# STM32N655 register map
File version: 1.0
CPU: CM55 r0p1, little endian, no MPU, FPU, vendor SysTick, 8 interrupt priority bits
Registers are 32-bit, read-write, reset 0x0 unless marked. A register's access mark holds for its fields unless they carry their own. Offsets are from the block's base; [hi:lo] are bit positions; {n}, {i} and the like mark numbered series; 'fields as' and 'values as' point back to an identical list.

## FMC1 — Flexible memory controller
Base 0x48024000
Same registers: FMC1_S 0x58024000
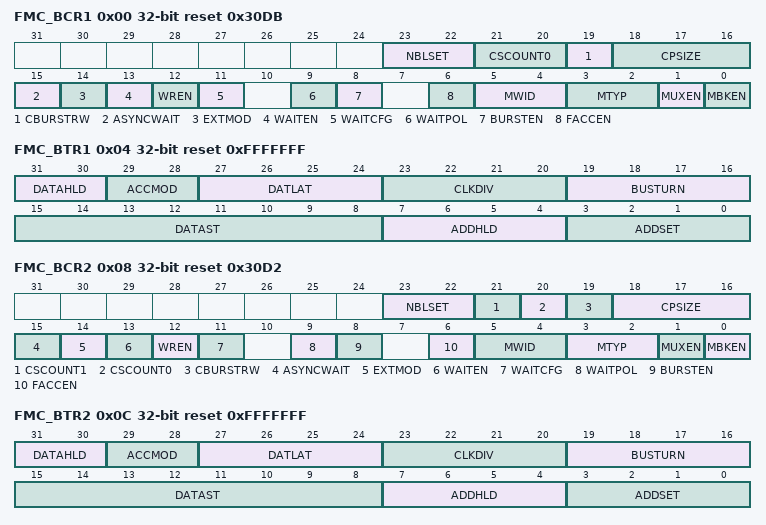
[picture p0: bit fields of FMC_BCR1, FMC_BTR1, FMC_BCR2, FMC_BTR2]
0x00 FMC_BCR1 reset 0x30DB — SRAM/NOR Flash chip-select control register for memory region 1
  [23:22] NBLSET — Byte lane (NBL) setup
    0=NBL setup time is 0 fmc_ker_ck clock cycle; 1=NBL setup time is 1 fmc_ker_ck clock cycle; 2=NBL setup time is 2 fmc_ker_ck clock cycles; 3=NBL setup time is 3 fmc_ker_ck clock cycles
  [21:20] CSCOUNT0 — Chip Select (CS) counter
    0=Counter disabled; 1=NEx deasserted after fmc_ker_ck clock cycle; 2=NEx deasserted after 64 fmc_ker_ck clock cycles; 3=NEx deasserted after 256 fmc_ker_ck clock cycles
  [19] CBURSTRW — Write burst enable
    0=Write operations are always performed in asynchronous mode; 1=Write operations are performed in synchronous mode
  [18:16] CPSIZE — CRAM page size
    0=No burst split when crossing page boundary. (default after reset).; 1=128 bytes; 2=256 bytes; 3=512 bytes; 4=1024 bytes
  [15] ASYNCWAIT — Wait signal during asynchronous transfers
    0=NWAIT signal not taken in to account during asynchronous transfers (default after reset); 1=NWAIT signal taken in to account during asynchronous transfers
  [14] EXTMOD — Extended mode enable
    0=Values inside FMC_BWTR register not taken into account (default after reset); 1=Values inside FMC_BWTR register taken into account
  [13] WAITEN — Wait enable bit
    0=NWAIT signal disabled (its level not taken into account, no wait state inserted after the programmed Flash latency period); 1=NWAIT signal enabled (its level is taken into account after the programmed latency period to insert wait states if asserted) (default after reset)
  [12] WREN — Write enable bit
    0=Write operations to the memory region by the FMC disabled. An AXI slave error is reported,; 1=Write operations to the memory region by the FMC enabled (default after reset)
  [11] WAITCFG — Wait timing configuration
    0=NWAIT signal active one data cycle before wait state (default after reset),; 1=NWAIT signal active during wait state (not used for PSRAM)
  [9] WAITPOL — Wait signal polarity bit
    0=NWAIT active low (default after reset),; 1=NWAIT active high
  [8] BURSTEN — Burst enable bit
    0=Burst mode disabled (default after reset). Read accesses are performed in asynchronous mode.; 1=Burst mode enable. Read accesses are performed in synchronous mode.
  [6] FACCEN — Flash memory access enable
    0=Corresponding NOR Flash memory access is disabled; 1=Corresponding NOR Flash memory access is enabled (default after reset)
  [5:4] MWID — Memory data bus width
    0=8 bits; 1=16 bits (default after reset); 2=32 bits
  [3:2] MTYP — Memory type
    0=SRAM/ FRAM (default after reset for memory region 2...4); 1=PSRAM (CRAM)/FRAM; 2=NOR Flash/OneNAND Flash (default after reset for memory region 1)
  [1] MUXEN — Address/data multiplexing enable bit
    0=Address/Data non-multiplexed; 1=Address/Data multiplexed on databus (default after reset)
  [0] MBKEN — Memory region enable bit
    0=Corresponding memory region is disabled; 1=Corresponding memory region is enabled
0x04 FMC_BTR1 reset 0xFFFFFFF — SRAM/NOR Flash chip-select timing registers for memory region 1
  [31:30] DATAHLD — Data Hold phase duration
    0=DATAHLD phase duration = fmc_ker_ck clock cycle * 0 (default, read)/1 (default, write); 1=DATAHLD phase duration = fmc_ker_ck clock cycle * 1 (read)/2 (write); 2=DATAHLD phase duration = fmc_ker_ck clock cycle * 2 (read)/3 (write); 3=DATAHLD phase duration = fmc_ker_ck clock cycle * 3 (read)/4 (write)
  [29:28] ACCMOD — Access mode
    0=Access mode A; 1=Access mode B; 2=Access mode C; 3=Access mode D
  [27:24] DATLAT — Data latency for synchronous memory (see note below bit descriptions)
    0=Data latency of 2 FMC_CLK clock cycles for first burst access; 15=Data latency of 17 FMC_CLK clock cycles for first burst access (default value after reset)
  [23:20] CLKDIV — Clock divide ratio (for FMC_CLK signal)
    0=FMC_CLK period= 1x fmc_ker_ck period; 1=FMC_CLK period = 2 fmc_ker_ck periods; 2=FMC_CLK period = 3 fmc_ker_ck periods; 15=FMC_CLK period = 16 fmc_ker_ck periods (default value after reset)
  [19:16] BUSTURN — Bus turnaround phase duration
    0=BUSTURN phase duration = 1 * fmc_ker_ck clock cycle added; 15=BUSTURN phase duration = 16 * fmc_ker_ck clock cycles added (default value after reset)
  [15:8] DATAST — Data-phase duration
    1=DATAST phase duration = 1 * fmc_ker_ck clock cycles; 2=DATAST phase duration = 2 * fmc_ker_ck clock cycles; 255=DATAST phase duration = 255 * fmc_ker_ck clock cycles (default value after reset)
  [7:4] ADDHLD — Address-hold phase duration
    1=ADDHLD phase duration =1 * fmc_ker_ck clock cycle; 2=ADDHLD phase duration = 2 * fmc_ker_ck clock cycle; 15=ADDHLD phase duration = 15 * fmc_ker_ck clock cycles (default value after reset)
  [3:0] ADDSET — Address setup phase duration
    0=ADDSET phase duration = 0 * fmc_ker_ck clock cycle; 15=ADDSET phase duration = 15 * fmc_ker_ck clock cycles (default value after reset)
0x08 FMC_BCR2 reset 0x30D2 — SRAM/NOR Flash chip-select control register for memory region 2
  [23:22] NBLSET — Byte lane (NBL) setup
    values as FMC_BCR1.NBLSET
  [21] CSCOUNT1 — Chip Select (CS) counter
    0=Counter disabled; 1=NEx deasserted after fmc_ker_ck clock cycle
  [20] CSCOUNT0 — Chip Select (CS) counter
    values as CSCOUNT1
  [19] CBURSTRW — Write burst enable
    values as FMC_BCR1.CBURSTRW
  [18:16] CPSIZE — CRAM page size
    values as FMC_BCR1.CPSIZE
  [15] ASYNCWAIT — Wait signal during asynchronous transfers
    values as FMC_BCR1.ASYNCWAIT
  [14] EXTMOD — Extended mode enable
    values as FMC_BCR1.EXTMOD
  [13] WAITEN — Wait enable bit
    values as FMC_BCR1.WAITEN
  [12] WREN — Write enable bit
    values as FMC_BCR1.WREN
  [11] WAITCFG — Wait timing configuration
    values as FMC_BCR1.WAITCFG
  [9] WAITPOL — Wait signal polarity bit
    values as FMC_BCR1.WAITPOL
  [8] BURSTEN — Burst enable bit
    values as FMC_BCR1.BURSTEN
  [6] FACCEN — Flash memory access enable
    values as FMC_BCR1.FACCEN
  [5:4] MWID — Memory data bus width
    0=8 bits; 1=16 bits (default after reset); 2=32 bits
  [3:2] MTYP — Memory type
    values as FMC_BCR1.MTYP
  [1] MUXEN — Address/data multiplexing enable bit
    values as FMC_BCR1.MUXEN
  [0] MBKEN — Memory region enable bit
    values as FMC_BCR1.MBKEN
0x0C FMC_BTR2 reset 0xFFFFFFF — SRAM/NOR Flash chip-select timing registers for memory region 2
  fields as FMC_BTR1
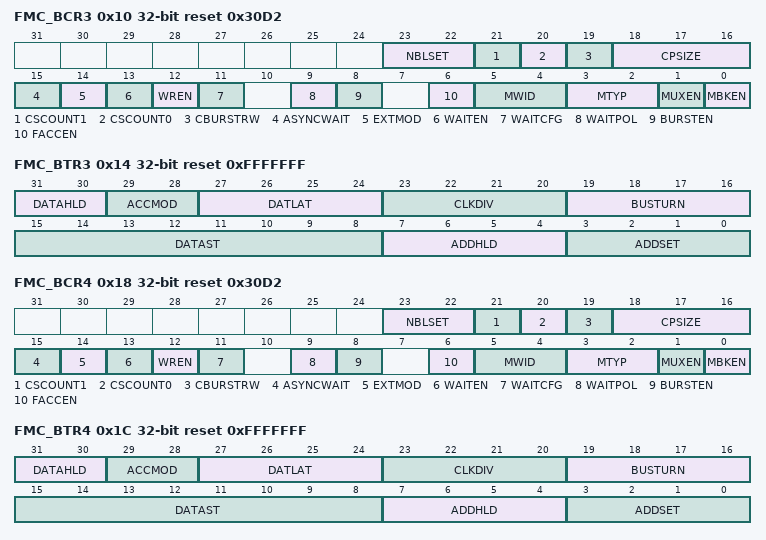
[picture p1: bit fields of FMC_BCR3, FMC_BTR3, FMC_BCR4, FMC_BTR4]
0x10 FMC_BCR3 reset 0x30D2 — SRAM/NOR Flash chip-select control register for memory region 3
  fields as FMC_BCR2
0x14 FMC_BTR3 reset 0xFFFFFFF — SRAM/NOR Flash chip-select timing registers for memory region 3
  fields as FMC_BTR1
0x18 FMC_BCR4 reset 0x30D2 — SRAM/NOR Flash chip-select control register for memory region 4
  fields as FMC_BCR2
0x1C FMC_BTR4 reset 0xFFFFFFF — SRAM/NOR Flash chip-select timing registers for memory region 4
  fields as FMC_BTR1
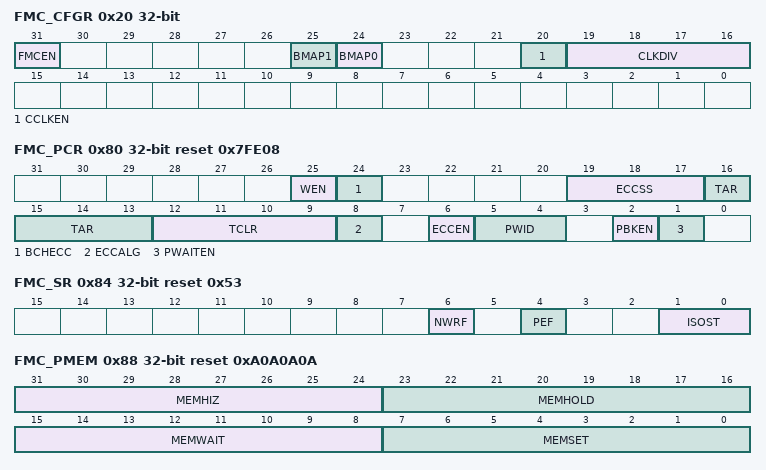
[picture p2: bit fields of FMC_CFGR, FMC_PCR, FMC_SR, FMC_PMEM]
0x20 FMC_CFGR — FMC common configuration register
  [31] FMCEN — FMC controller enable
    0=FMC controller disabled; 1=FMC controller enabled
  [25] BMAP1 — FMC memory region mapping
    0=Default mapping (refer to Table 132); 1=Devices are remapped (refer to Table 133)
  [24] BMAP0 — FMC memory region mapping
    values as BMAP1
  [20] CCLKEN — Continuous clock enable
    0=The FMC_CLK is only generated during the synchronous memory access (read/write transaction). The FMC_CLK clock ratio is defined by the programmed CLKDIV value in the FMC_BCRx register (default after reset).; 1=The FMC_CLK is generated continuously during asynchronous and synchronous access
  [19:16] CLKDIV — Clock divide ratio (for FMC_CLK signal)
    values as FMC_BTR1.CLKDIV
0x80 FMC_PCR reset 0x7FE08 — NAND Flash programmable control register
  [25] WEN — Write enable
    0=Read access enabled; 1=Write access enabled
  [24] BCHECC — BCH error correction capability
    0=4-bit BCH (4-bit error correction and 8-bit error detection per 512 bytes); 1=8-bit BCH (8-bit error correction and 16-bit error detection per 512 bytes)
  [19:17] ECCSS — ECC sector size (used to access spare area)
    0=256 bytes; 1=512 bytes; 2=1024 bytes; 3=2048 bytes (default); 4=4096 bytes
  [16:13] TAR — ALE to RE delay.
    0=1 * fmc_ker_ck cycle; 15=16 * fmc_ker_ck cycles (default)
  [12:9] TCLR — CLE to RE delay.
    0=1 * fmc_ker_ck cycle; 15=16 * fmc_ker_ck cycles (default)
  [8] ECCALG — ECC algorithm
    0=Hamming code is selected (default); 1=BCH code is selected
  [6] ECCEN — ECC computation logic enable bit
    0=ECC logic is disabled and reset (default after reset),; 1=ECC logic is enabled
  [5:4] PWID — Data bus width
    0=8 bits (default after reset); 1=16 bits
  [2] PBKEN — NAND Flash memory region enable bit
    0=Corresponding memory region is disabled (default after reset); 1=Corresponding memory region is enabled
  [1] PWAITEN — Wait feature enable bit
    0=disabled (default); 1=enabled
0x84 FMC_SR ro reset 0x53 — FMC status register
  [6] NWRF — NAND write request flag
    0=NAND Flash write requests are pending; 1=No NAND Flash write requests pending
  [4] PEF — Pipe Empty Flag
  [1:0] ISOST — FMC isolation state with respect to the AXI interface
    0=FMC is not isolated; AXI transactions are treated by the FMC and its controllers; 1=FMC has been enabled (FMCEN = 1) and waits for the end of pending AXI transactions (which leads to error responses) before going to non-isolated state; 2=FMC has been disabled (FMCEN = 0) and waits for the end of pending AXI transactions before going to isolation state; 3=FMC is isolated from its AXI interface. All AXI requests lead to error responses.
0x88 FMC_PMEM reset 0xA0A0A0A — FMC common memory space timing register
  [31:24] MEMHIZ — Common memory data bus Hi-Z time
    0=1 * fmc_ker_ck cycle; 1=2 * fmc_ker_ck cycles; 255=256 * fmc_ker_ck cycles
  [23:16] MEMHOLD — Common memory hold time
    values as MEMHIZ
  [15:8] MEMWAIT — Common memory wait time
    0=1 * fmc_ker_ck cycles (+ wait cycle introduced by deasserting NWAIT); 1=2 * fmc_ker_ck cycles (+ wait cycle introduced by deasserting NWAIT); 255=256 * fmc_ker_ck cycles (+ wait cycle introduced by deasserting NWAIT)
  [7:0] MEMSET — Common memory setup time
    0=1 * fmc_ker_ck cycles; 1=2 * fmc_ker_ck cycles; 255=256 * fmc_ker_ck cycles
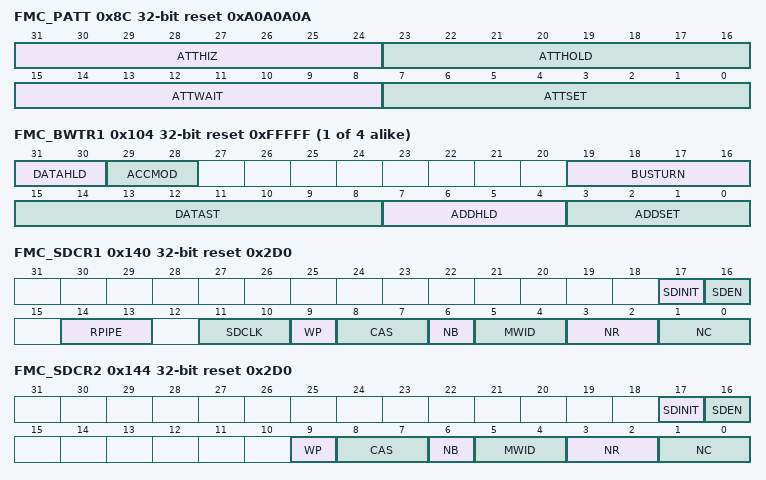
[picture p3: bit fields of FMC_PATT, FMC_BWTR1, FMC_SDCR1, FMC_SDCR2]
0x8C FMC_PATT reset 0xA0A0A0A — FMC attribute memory space timing registers
  [31:24] ATTHIZ — Attribute memory data bus Hi-Z time
    0=1 * fmc_ker_ck cycle; 1=2 * fmc_ker_ck cycle; 255=256 * fmc_ker_ck cycles
  [23:16] ATTHOLD — Attribute memory hold time
    values as ATTHIZ
  [15:8] ATTWAIT — Attribute memory wait time
    0=1 * fmc_ker_ck cycle (+ wait cycle introduced by deassertion of NWAIT); 1=2 * fmc_ker_ck cycles (+ wait cycle introduced by deassertion of NWAIT); 255=256 * fmc_ker_ck cycles (+ wait cycle introduced by deasserting NWAIT)
  [7:0] ATTSET — Attribute memory setup time
    values as ATTHIZ
0x90 FMC_HPR ro — FMC Hamming parity result registers
  [31:0] HPR — Hamming parity result
0x94 FMC_HECCR ro — FMC Hamming code ECC result register
  [31:0] HECC — ECC result
{0xFC+8i} FMC_BWTR{i} reset 0xFFFFF (i=1..4) — SRAM/NOR-Flash write timing registers for memory region {i}
  [31:30] DATAHLD — Data Hold phase duration
    0=DATAHLD phase duration = 1 * fmc_ker_ck clock cycle (default); 1=DATAHLD phase duration = 2 * fmc_ker_ck clock cycle; 2=DATAHLD phase duration = 3 * fmc_ker_ck clock cycle; 3=DATAHLD phase duration = 4 * fmc_ker_ck clock cycle
  [29:28] ACCMOD — Access mode.
    values as FMC_BTR1.ACCMOD
  [19:16] BUSTURN — Bus turnaround phase duration
    values as FMC_BTR1.BUSTURN
  [15:8] DATAST — Data-phase duration.
    values as FMC_BTR1.DATAST
  [7:4] ADDHLD — Address-hold phase duration.
    1=ADDHLD phase duration = 1 * fmc_ker_ck clock cycle; 2=ADDHLD phase duration = 2 * fmc_ker_ck clock cycle; 15=ADDHLD phase duration = 15 * fmc_ker_ck clock cycles (default value after reset)
  [3:0] ADDSET — Address setup phase duration.
    values as FMC_BTR1.ADDSET
0x140 FMC_SDCR1 reset 0x2D0 — SDRAM control registers for SDRAM device 1
  [17] SDINIT — SDRAM device initialization
    1=Initialization is complete and the device is ready to be accessed; 0=Initialization is not complete, the AXI accesses are rejected and an AXI slave error is generated
  [16] SDEN — SDRAM device enable
    1=SDRAM device enabled; 0=SDRAM disabled
  [14:13] RPIPE — Read pipe
    0=No fmc_ker_ck clock cycle delay (default value); 1=One fmc_ker_ck clock cycle delay; 2=Two fmc_ker_ck clock cycle delay
  [11:10] SDCLK — SDRAM clock configuration
    0=SDCLK clock disabled; 1=SDCLK period = 1 * fmc_ker_ck period; 2=SDCLK period = 2 * fmc_ker_ck periods; 3=SDCLK period = 3 * fmc_ker_ck periods
  [9] WP — Write protection
    0=Write accesses allowed; 1=Write accesses ignored
  [8:7] CAS — CAS Latency
    1=1 cycle; 2=2 cycles; 3=3 cycles
  [6] NB — Number of banks
    0=Two banks; 1=Four banks
  [5:4] MWID — Memory data bus width.
    0=8 bits; 1=16 bits; 2=32 bits
  [3:2] NR — Number of row address bits
    0=11 bit; 1=12 bits; 2=13 bits
  [1:0] NC — Number of column address bits
    {v}={v+8} bits (v=0..3)
0x144 FMC_SDCR2 reset 0x2D0 — SDRAM control registers for SDRAM device 2
  [17] SDINIT — SDRAM device initialization
    values as FMC_SDCR1.SDINIT
  [16] SDEN — SDRAM device enable
    1=SDRAM device enabled; 0=SDRAM disabled
  [9] WP — Write protection
    0=Write accesses allowed; 1=Write accesses ignored
  [8:7] CAS — CAS Latency
    1=1 cycle; 2=2 cycles; 3=3 cycles
  [6] NB — Number of banks
    0=Two banks; 1=Four banks
  [5:4] MWID — Memory data bus width.
    0=8 bits; 1=16 bits; 2=32 bits
  [3:2] NR — Number of row address bits
    0=11 bit; 1=12 bits; 2=13 bits
  [1:0] NC — Number of column address bits
    {v}={v+8} bits (v=0..3)
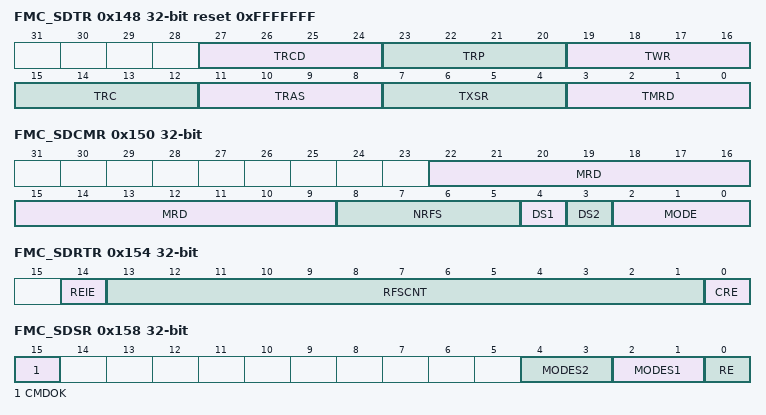
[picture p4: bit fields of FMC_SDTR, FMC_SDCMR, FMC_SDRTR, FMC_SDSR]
0x148 FMC_SDTR reset 0xFFFFFFF — SDRAM timing register
  [all] fields
    0=1 cycle; 1=2 cycles; 15=16 cycles
  [27:24] TRCD — Row to column delay
  [23:20] TRP — Row precharge delay
  [19:16] TWR — Recovery delay
  [15:12] TRC — Row cycle delay
  [11:8] TRAS — Self-refresh time
  [7:4] TXSR — Exit self-refresh delay
  [3:0] TMRD — Load mode register to active
0x150 FMC_SDCMR access per field — SDRAM command mode register
  [22:9] MRD rw — Mode register definition
  [8:5] NRFS rw — Number of Refresh commands
    0=1 Refresh cycle; 1=2 Refresh cycles; 14=15 Refresh cycles; 15=16 Refresh cycles
  [4] DS1 wo — Command targeting SDRAM device 1
    0=Command not issued to SDRAM device 1; 1=Command issued to SDRAM device 1
  [3] DS2 wo — Command targeting SDRAM device 2
    0=Command not issued to SDRAM device 2; 1=Command issued to SDRAM device 2
  [2:0] MODE wo — Command mode
    0=Normal mode command (NRM); 2=Precharge all banks command (PALL); 3=Refresh command (REF); 4=Load mode register command (LMR); 5=Self-refresh command (SR); 6=Power-down command (PD)
0x154 FMC_SDRTR access per field — SDRAM refresh timer register
  [14] REIE rw — RES Interrupt Enable
    0=Interrupt is disabled; 1=An Interrupt is generated if RE = 1
  [13:1] RFSCNT rw — Refresh Timer Count
  [0] CRE wo — Clear Refresh error flag
    0=no effect; 1=Refresh Error flag is cleared
0x158 FMC_SDSR ro — SDRAM status register
  [15] CMDOK — Previous command status
    0=Command not complete; 1=Command complete in the SDRAM clock domain
  [4:3] MODES2 — Status mode for SDRAM device 2
    0=Normal mode, devices are not in Self-refresh or power-down; 1=Self-refresh; 2=Power-down
  [2:1] MODES1 — Status Mode for SDRAM device 1
    values as MODES2
  [0] RE — Refresh error flag
    0=No refresh error has been detected; 1=A refresh error has been detected
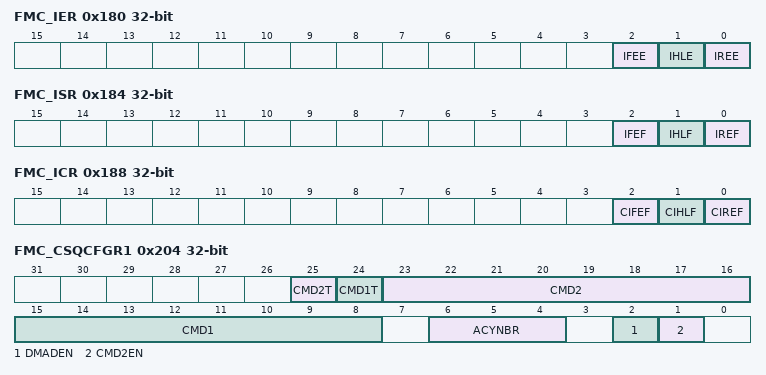
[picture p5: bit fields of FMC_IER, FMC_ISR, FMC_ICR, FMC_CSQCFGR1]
0x180 FMC_IER — FMC NAND interrupt enable register
  [2] IFEE — Interrupt falling edge detection enable bit
    0=Interrupt falling edge detection request disabled; 1=Interrupt falling edge detection request enabled
  [1] IHLE — Interrupt high-level detection enable bit
    0=Interrupt high-level detection request disabled; 1=Interrupt high-level detection request enabled
  [0] IREE — Interrupt rising edge detection enable bit
    0=Interrupt rising edge detection request disabled; 1=Interrupt rising edge detection request enabled
0x184 FMC_ISR ro — FMC controller interrupt status register
  [2] IFEF — Interrupt falling edge flag
    0=No interrupt falling edge occurred; 1=Interrupt falling edge occurred
  [1] IHLF — Interrupt high-level flag
    0=No Interrupt high-level occurred; 1=Interrupt high-level occurred
  [0] IREF — Interrupt rising edge flag
    0=No interrupt rising edge occurred; 1=Interrupt rising edge occurred
0x188 FMC_ICR wo — FMC NAND controller interrupt clear register
  [2] CIFEF — Clear Interrupt falling edge flag
    0=No effect; 1=Clears the IFEF flag in the FMC_ISR register
  [1] CIHLF — Clear Interrupt high-level flag
    0=No effect; 1=Clears the IHLF flag in the FMC_ISR register
  [0] CIREF — Clear Interrupt rising edge flag
    0=No effect; 1=Clear the IREF flag in the FMC_ISR register
0x200 FMC_CSQCR wo — FMC NAND command sequencer control register
  [0] CSQSTART — Command Sequencer Enable
0x204 FMC_CSQCFGR1 — FMC NAND command sequencer configuration register 1
  [25] CMD2T — Command 2 Sequencer timings
    0=CMD2 issued with the timings programmed in FMC_PMEM; 1=CMD2 issued with the timings programmed in FMC_PATT
  [24] CMD1T — Command 1 Sequencer timings
    0=CMD1 issued with the timings programmed in FMC_PMEM; 1=CMD1 issued with the timings programmed in FMC_PATT
  [23:16] CMD2 — Command 2 sequencer
  [15:8] CMD1 — Command 1 sequencer
  [6:4] ACYNBR — Address Cycle number
    0=No address cycle; 1=1 address cycle; {v}={v} address cycles (v=2..5)
  [2] DMADEN — Command sequencer DMA request data enable
    0=No DMA request transfer; 1=A DMA request transfer
  [1] CMD2EN — Command cycle 2 Enable
    0=Command cycle 2 not issued; 1=Command cycle 2 (programmed CMD2[7:0]) sent by the command sequencer to the NAND Flash memory after the address cycles
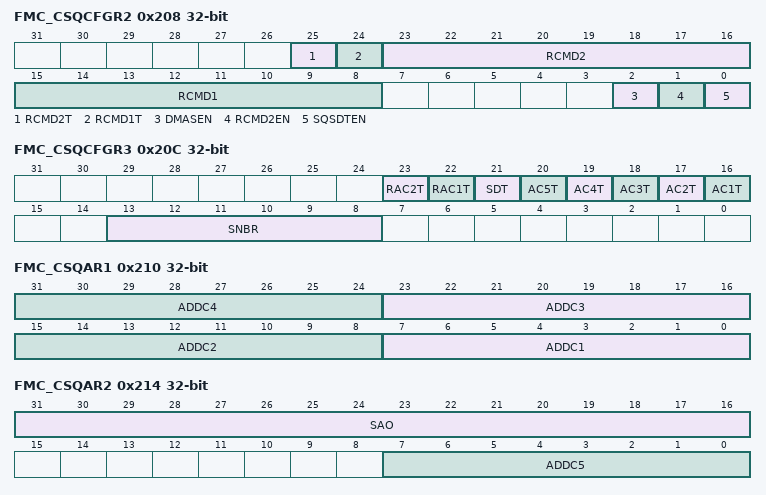
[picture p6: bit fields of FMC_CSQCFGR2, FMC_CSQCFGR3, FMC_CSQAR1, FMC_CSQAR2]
0x208 FMC_CSQCFGR2 — FMC NAND command sequencer configuration register 2
  [25] RCMD2T — Command 1 sequencer timings
    values as FMC_CSQCFGR1.CMD1T
  [24] RCMD1T — Command 1 sequencer timings
    values as FMC_CSQCFGR1.CMD1T
  [23:16] RCMD2 — Random Command 2 sequencer
  [15:8] RCMD1 — Random Command 1 sequencer
  [2] DMASEN — Command sequencer DMA request decoding status enable
    0=No DMA request used for ECC status registers transfer; 1=A DMA request used for ECC status registers transfer
  [1] RCMD2EN — Random Command 2 sequencer enable
    0=Command 2 not issued; 1=Command 2 (CMD2SQ[7:0]) issued by the command sequencer to NAND flash memory after the address cycle
  [0] SQSDTEN — Sequencer spare data transfer enable
    0=ECC disabled and spare data area not accessed by the sequencer; 1=ECC enabled and spare data area read or programmed by the sequencer after each sector transfer
0x20C FMC_CSQCFGR3 — FMC NAND sequencer configuration register 3
  [23] RAC2T — Random Address cycle 2 sequencer timings
    0=Random ADDC2 issued with the timings programmed in FMC_PMEM; 1=Random ADDC2 issued with the timings programmed in FMC_PATT
  [22] RAC1T — Random Address cycle 1 sequencer timings
    0=Random ADDC1 issued with the timings programmed in FMC_PMEM; 1=Random ADDC1 issued with the timings programmed in FMC_PATT
  [21] SDT — Spare data transfer sequencer timings
    0=Spare data transfer issued with the timings programmed in FMC_PMEM; 1=Spare data transfer issued with the timings programmed in FMC_PATT
  [20] AC5T — Address cycle 5 sequencer timings
    0=ADDC5 issued with the timings programmed in FMC_PMEM; 1=ADDC5 issued with the timings programmed in FMC_PATT
  [19] AC4T — Address cycle 4sequencer timings
    0=ADDC4 issued with the timings programmed in FMC_PMEM; 1=ADDC4 issued with the timings programmed in FMC_PATT
  [18] AC3T — Address cycle 3 sequencer timings
    0=ADDC3 issued with the timings programmed in FMC_PMEM; 1=ADDC3 issued with the timings programmed in FMC_PATT
  [17] AC2T — Address cycle 2 sequencer timings
    0=ADDC2 issued with the timings programmed in FMC_PMEM; 1=ADDC2 issued with the timings programmed in FMC_PATT
  [16] AC1T — Address cycle 1 sequencer timings
    0=ADDC1 issued with the timings programmed in FMC_PMEM; 1=ADDC1 issued with the timings programmed in FMC_PATT
  [13:8] SNBR — Number of sectors to be read/written
    0=1 sector; 1=2 sectors; 63=16 sectors
0x210 FMC_CSQAR1 — FMC NAND command sequencer address register 1
  [8n-1:8n-8] ADDC{n} (n=1..4) — Address Cycle {n}
0x214 FMC_CSQAR2 — FMC NAND command sequencer address register 2
  [31:16] SAO — Spare Area Address Offset
  [7:0] ADDC5 — Address Cycle 5
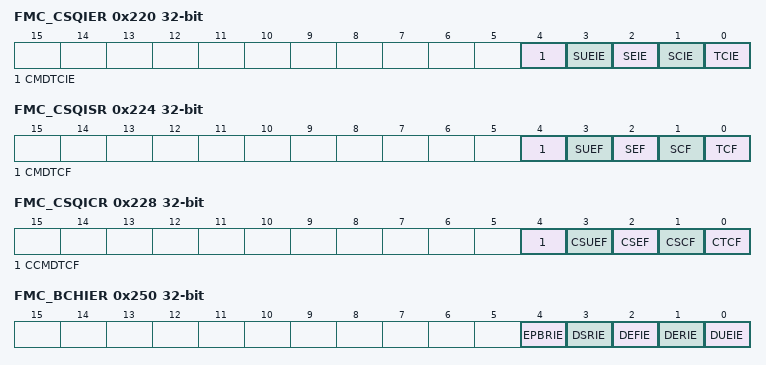
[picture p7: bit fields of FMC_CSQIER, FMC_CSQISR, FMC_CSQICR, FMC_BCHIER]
0x220 FMC_CSQIER — FMC NAND command sequencer interrupt enable register
  [4] CMDTCIE — Command Transfer Complete interrupt enable
    0=Command Transfer Complete Interrupt disable; 1=Command Transfer Complete Interrupt enable
  [3] SUEIE — Sector Uncorrectable Error interrupt enable
    values as CMDTCIE
  [2] SEIE — Sector Error interrupt enable
    0=Sector Error Interrupt disable; 1=Sector Error Interrupt enable
  [1] SCIE — Sector Complete interrupt enable
    0=Sector Complete Interrupt disable; 1=Sector Complete Interrupt enable
  [0] TCIE — Transfer Complete Interrupt enable
    0=Transfer Complete Interrupt disable; 1=Transfer Complete Interrupt enable
0x224 FMC_CSQISR — FMC NAND command sequencer interrupt status register
  [4] CMDTCF — Command Transfer Complete flag
  [3] SUEF — Sector Uncorrectable Error flag
  [2] SEF — Sector Error flag
  [1] SCF — Sector Complete flag
  [0] TCF — Transfer Complete flag
0x228 FMC_CSQICR wo — FMC NAND command sequencer interrupt clear register
  [4] CCMDTCF — Clear Command Transfer Complete flag
  [3] CSUEF — Clear Sector uncorrectable Error flag
  [2] CSEF — Clear Sector Error flag
  [1] CSCF — Clear Sector Complete flag
  [0] CTCF — Clear Transfer Complete flag
0x230 FMC_CSQEMSR ro — FMC command sequencer error mapping status register
  [15:0] SEM — Sector Error mapping
0x250 FMC_BCHIER — FMC BCH interrupt enable register
  [4] EPBRIE — Decoder Parity Bits Ready Interrupt enable
    0=Decoder Parity Bits Ready Interrupt disable; 1=Decoder Parity Bits Ready Interrupt enable
  [3] DSRIE — Decoder Syndrome Ready Interrupt enable
    0=Decoder Syndrome Ready Interrupt disable; 1=Decoder Syndrome Ready Interrupt enable
  [2] DEFIE — Decoder Error Found Interrupt enable
    0=Decoder Error Found Interrupt disable; 1=Decoder Error Found Interrupt enable
  [1] DERIE — Decoder Error Ready Interrupt enable
    0=Decoder Error Ready Interrupt disable; 1=Decoder Error Ready Interrupt enable
  [0] DUEIE — Decoder Uncorrectable Errors Interrupt enable
    0=Decoder Uncorrectable Errors Interrupt disable; 1=Decoder Uncorrectable Errors Interrupt enable
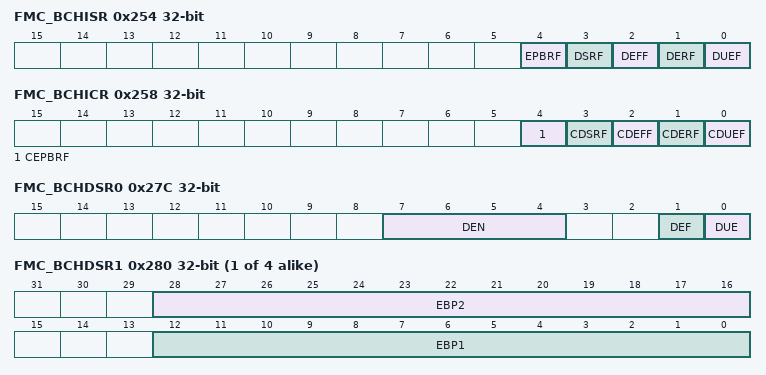
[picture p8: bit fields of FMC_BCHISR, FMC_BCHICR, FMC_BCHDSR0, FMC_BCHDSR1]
0x254 FMC_BCHISR ro — FMC BCH interrupt and status register
  [4] EPBRF — Encoder Parity Bits Ready flag
  [3] DSRF — Decoder Syndrome Ready flag
  [2] DEFF — Decoder Error Found flag
  [1] DERF — Decoder Error Ready flag
  [0] DUEF — Decoder Uncorrectable Errors flag
0x258 FMC_BCHICR wo — FMC BCH interrupt clear register
  [4] CEPBRF — Clear Encoder Parity Bits Ready flag
  [3] CDSRF — Clear Decoder Syndrome Ready flag
  [2] CDEFF — Clear Decoder Error Found flag
  [1] CDERF — Clear Decoder Error ready flag
  [0] CDUEF — Clear Decoder Uncorrectable Error flag
{0x25C+4i} FMC_BCHPBR{i} ro (i=1..3) — FMC BCH parity bits register {i}
  [31:0] BCHPB — BCH parity bits
0x26C FMC_BCHPBR4 ro — FMC BCH parity bits register 4
  [7:0] BCHPB — BCH parity bits
0x27C FMC_BCHDSR0 ro — FMC BCH decoder status register 0
  [7:4] DEN — Decoder error number
  [1] DEF — Decoder error found
  [0] DUE — Decoder uncorrectable error
{0x27C+4i} FMC_BCHDSR{i} ro (i=1..4) — FMC BCH decoder status register for memory region {i}
  [28:16] EBP{2i} — Error bit position for error number {2i}
  [12:0] EBP{2i-1} — Error bit position for error number {2i-1}
